# J7AEP_GPU_BXS464_WRAP0_GPU_SS_0_CORE_MMRS register map
Vendor: Texas Instruments
Registers are 64-bit, access per field, reset 0x0 unless marked. A register's access mark holds for its fields unless they carry their own. Offsets are as the file gives them; [hi:lo] are bit positions; lines under a group give offsets from that group; {n}, {i} and the like mark numbered series; 'fields as' and 'values as' point back to an identical list.

## J7AEP_GPU_BXS464_WRAP0_GPU_SS_0_CORE_MMRS (part 3 of 5)
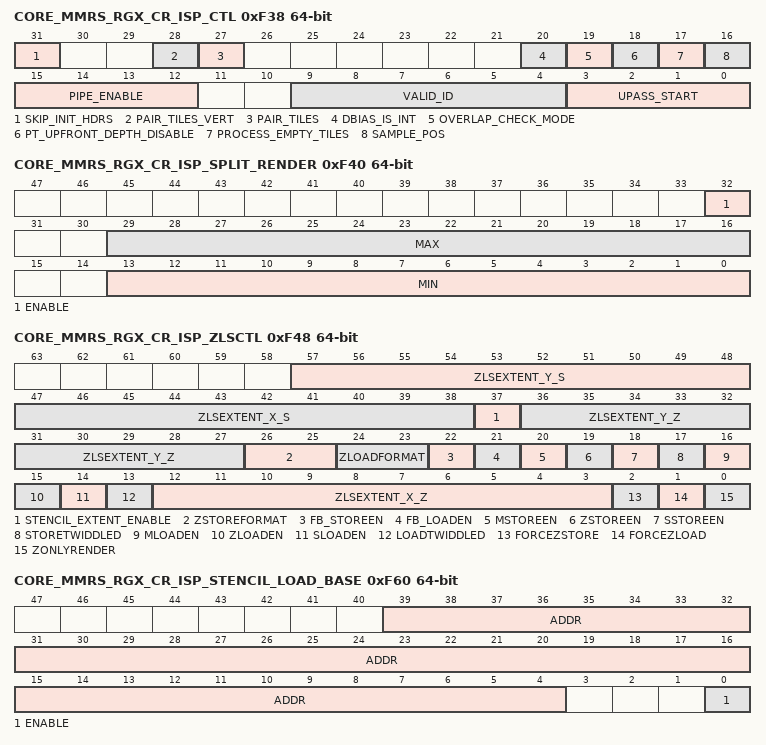
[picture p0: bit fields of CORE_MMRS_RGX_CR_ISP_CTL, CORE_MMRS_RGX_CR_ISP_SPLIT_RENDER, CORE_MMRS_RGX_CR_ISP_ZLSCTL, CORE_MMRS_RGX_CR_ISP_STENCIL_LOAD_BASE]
0xF38 CORE_MMRS_RGX_CR_ISP_CTL — ISP control register. This register contains the PIPE_NUM field which controls the number of tiles in flight within the IPP and IPF. The values to which this register should be set are dependent on not only the number of tiles in flight that are desired, but also the version of the architecture in use. For REL 1,2 Cores, this register can be programmed to values of 0x0-0x2 inclusive enabling 1, 2 and 3 tiles in flight for the single ISP in the system. In this system the IPP and IPF are both present in the same layout block. For REL 3,7 Cores, the IPP module is remote from the ISP module as the ISP belongs to the scalable elements in the design. A Cluster Group refers to the 4 USCs in a Phantom Block, which also contains an ISP. 1 Cluster Group = 1 IPP, and 1 ISP, 2 Cluster Groups = 1 IPP and 2 ISPs. The IPP module is configured using the register, and the tiles are split between them via the LSB of the Pipe Identifier. When 2 Cluster Groups (6 or 8 USC clusters) are present, as the value of PIPE_NUM is increased, the tile in flight are spread equally between ISP0 and ISP1, as below 0x0: - ISP0 (1 tile in flight) - ISP1 (Not Used - IDLE Pipe) 0x1: - ISP0 (1 tile in flight) - ISP1 (1 tile in flight) 0x2: - ISP0 (2 tiles in flight) - ISP1 (1 tile in flight) 0x3: - ISP0 (2 tiles in flight) - ISP1 (2 tiles in flight) 0x4: - ISP0 (3 tiles in flight) - ISP1 (2 tiles in flight) 0x5: - ISP0 (3 tiles in flight) - ISP1 (3 tiles in flight) 0x6: - ISP0 (4 tiles in flight) - ISP1 (3 tiles in flight) 0x7: - ISP0 (4 tiles in flight) - ISP1 (4 tiles in flight) Value of 0,2,4,6 should never be use on a 8 USC system, as they result in internal GPU imbalance. When 1 Cluster Group is present (1,2,4 USC clusters) , as the value of PIPE_NUM is increased, the tiles in flight will increase every power of 2, since ISP1 is not present. 0x0: - ISP0 (1 tile in flight) 0x2: - ISP0 (2 tiles in flight) 0x4: - ISP0 (3 tiles in flight) 0x6: - ISP0 (4 tiles in flight) A value which is higher than the number of IPF pipelines will result in the maximum number of pipelines being used. However, the number of pipelines being used should always be less than or equal to the number of tiles which the USC is able to concurrently process (i. e. the number of partitions). In a 4 or 8 cluster system there is 1 partition per tile. In a 2 cluster system there are 2 partitions per tile and in a 1 cluster system there are 4 partitions per tile. Effectively this means this register should be programmed according to the number of partitions available in the USC. NUM_TILES_PER_USC: 00 : 1 tile 01 : 2 tiles in the flight per usc cluster enabled 11 : 2 tiles in the flight per usc cluster enabled
  [31] SKIP_INIT_HDRS rw — Used to enable skipping of initial region headers based on gpu offset '0': reads all region headers and discards the ones not needed. '1': skip reading of region headers based on gpu offset
  [28] PAIR_TILES_VERT rw — If set, causes IPF to pair tiles vertically within its pipeline.
  [27] PAIR_TILES rw — If set, causes IPF to pair tiles within its pipeline.
  [20] DBIAS_IS_INT rw — When set, depth bias value is a signed integer
  [19] OVERLAP_CHECK_MODE rw — 0 - different samples for the same pixel will be sent to different pass groups for translucent objects [pixel to pixel overlap test] 1 - different samples for the same pixel will be sent as the same pass group [sample to sample overlap test]
  [18] PT_UPFRONT_DEPTH_DISABLE rw — When set, disable UPFRONT depth test in the Depthsorter
  [17] PROCESS_EMPTY_TILES rw — When set empty tiles are always processed rather than being suppressed
  [16] SAMPLE_POS rw — Specifies the sampling rule to be used when calculating the endpoint adjustment for thin lines
  [15:12] PIPE_ENABLE rw — Tiles-in-flight
  [9:4] VALID_ID rw — Triangle validation value
  [3:0] UPASS_START rw — User pass start value
0xF40 CORE_MMRS_RGX_CR_ISP_SPLIT_RENDER
  [32] ENABLE rw
  [29:16] MAX rw — Render up to and including this value
  [13:0] MIN rw — Render up from and including this value
0xF48 CORE_MMRS_RGX_CR_ISP_ZLSCTL — ISP Z Load/Store & format global control register
  [57:48] ZLSEXTENT_Y_S rw — For stencil buffer, the value calculation is the same as ZLSEXTENT_Y_Z
  [47:38] ZLSEXTENT_X_S rw — For stencil buffer, the value calculation is the same as ZLSEXTENT_X_Z
  [37] STENCIL_EXTENT_ENABLE rw — When this bit is '1', stencil buffer will use zlsextent_x/y_s value to calculate zload/store address, otherwise, zlsextent_x/y_z value will be used. The default value is '0' which disables this new function.
  [36:27] ZLSEXTENT_Y_Z rw — For Depth buffer Display width of Y in tiles minus one: 0x000 1 tile, 0x001 2 tiles, .. , 0x2FF 1024 tiles, zlsextent_y = total_samples_y / 32 samples in non-msaa, 4xmsaa mode = total_samples_y / 64 samples in 2xmsaa, 8xmsaa mode. In strided mode, zlsextent_y is set up to above result. In twiddled mode, zlsextent_y uses above result and rounds the value up to the nearest value which is power of 2.
  [26:25] ZSTOREFORMAT rw
  [24:23] ZLOADFORMAT rw
  [22] FB_STOREEN rw — when set, frame buffer compression store is enabled
  [21] FB_LOADEN rw — when set, frame buffer decompression load is enabled
  [20] MSTOREEN rw — When set and ZSTOREFORMAT = 0x0, mask plane is stored within msb of IEEE format, when set and ZSTOREFORMAT = 0x3, mask plane is stored at bit position 31 of IEEE format, when set for other format, if mask_store_base_enable = '1', background object mask data '0' is stored into separate memory address, when set for other format, if mask_store_base_enable = '0', mask data '0' is stored into separate meory address
  [19] ZSTOREEN rw — When set to 1, if the ZSTORE bit in the region header is also set then the depth buffer is stored to memory after each tile is processed
  [18] SSTOREEN rw — When set to 1, if the ZSTORE bit in the region header is also set then the stencil buffer is stored to memory after each tile is processed
  [17] STORETWIDDLED rw — When set to 1 depth and stencil data is written out in Twiddled order.
  [16] MLOADEN rw — When set and ZLOADFORMAT = 0x0, mask plane is loaded from msb of IEEE format, when set and ZLOADFORMAT = 0x3, mask plane is loaded from the bit position 31 of IEEE format, when set for other format, if mask_load_base_enable = '1', mask plane is loaded from separate memory address, when set for other format, if mask_load_base_enable = '0', background object mask data is used
  [15] ZLOADEN rw — When set to 1, if the ZLOAD bit in the region header is also set then the depth buffer is read from memory prior to tile processing
  [14] SLOADEN rw — When set to 1, if the ZLOAD bit in the region header is also set then the stencil buffer is read from memory prior to tile processing
  [13] LOADTWIDDLED rw — When set to 1 depth, stencil data is loaded in Twiddled order
  [12:3] ZLSEXTENT_X_Z rw — For depth buffer, Display width of X in tiles minus one: 0x000 1 tile, 0x001 2 tiles, .. , 0x2FF 1024 tiles. For different msaa mode, 1xmsaa = 1 x [32,32] pixels = 32x1 x 32x1 = 1024 samples = 32 x 32 samples, 2xmsaa = 2 x [32,32] pixels = 32x1 x 32x2 = 2048 samples = 32 x 64 samples, 4xmsaa = 4 x [32,16] pixels = 32x2 x 16x2 = 2048 samples = 64 x 32 samples, 8xmsaa = 8 x [16,16] pixels = 16x2 x 16x4 = 2048 samples = 32 x 64 samples, So zlsextent_x = total_samples_x / 32 samples when non-msaa, 2xmsaa, 8xmsaa zlsextent_x = total_samples_x / 64 samples when 4xmsaa In strided mode, zlsextent_x is set up to above result. In twiddled mode, zlsextent_x uses above result and rounds the value up to the neareast value which is power of 2.
  [2] FORCEZSTORE rw — If set to 1 the depth/stencil buffer is always stored at the end of each tile irrespective of the region header ZSTORE bit.
  [1] FORCEZLOAD rw — If set to 1 the depth/stencil buffer is always loaded at the start of each tile irrespective of the region header ZLOAD bit.
  [0] ZONLYRENDER rw — When set, only the Z buffer is rendered. Opaque and translucent objects are stencil and depth tested as usual but no pixel spans are emitted to the PDS Pixel presenter. Pixels within punch through and depth feedback objects are emitted on their first pass as a result of passing the up-front depth test by default. However, on their feedback depth test, these pixels will not be output regardless of the depth test result. The intention is to calculate a scene Z buffer without doing any further rendering.
0xF50 CORE_MMRS_RGX_CR_ISP_ZLOAD_BASE — Base address in memory of the Z Buffer base address to load into the ISP for non-compressed ZLS formats.
  [39:4] ADDR rw — 1TB Addressable, 16byte aligned Base Address of the Z Buffer Load base address
0xF58 CORE_MMRS_RGX_CR_ISP_ZSTORE_BASE — Base address in memory of the Z Buffer base address to store into the ISP for non-compressed ZLS formats.
  [39:4] ADDR rw — 1TB Addressable, 16byte aligned Base Address of the Z Buffer Store base address
0xF60 CORE_MMRS_RGX_CR_ISP_STENCIL_LOAD_BASE — Base address in memory of the Stencil Buffer base address to load into the ISP for non-compressed ZLS formats. This alternate stencil buffer base address is selectable based on the enable bit.
  [39:4] ADDR rw — 1TB Addressable, 16byte aligned Base Address of the Z Buffer Load base address
  [0] ENABLE rw — When set to 1, enables fetching of stencil from a separate base address
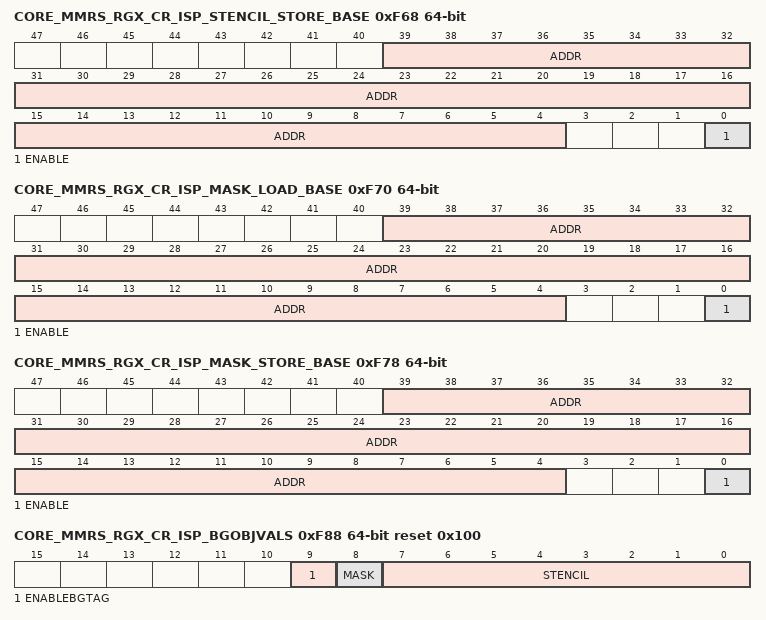
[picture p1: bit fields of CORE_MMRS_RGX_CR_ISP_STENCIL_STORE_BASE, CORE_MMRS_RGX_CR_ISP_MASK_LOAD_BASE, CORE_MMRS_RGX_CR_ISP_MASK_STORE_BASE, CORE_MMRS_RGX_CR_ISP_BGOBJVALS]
0xF68 CORE_MMRS_RGX_CR_ISP_STENCIL_STORE_BASE — Base address in memory of the Stencil Buffer base address to store into the ISP for non-compressed ZLS formats. This alternate stencil buffer base address is selectable based on the enable bit.
  fields as CORE_MMRS_RGX_CR_ISP_STENCIL_LOAD_BASE
0xF70 CORE_MMRS_RGX_CR_ISP_MASK_LOAD_BASE — Base address in memory of the Mask Buffer base address to load into the ISP for non-compressed ZLS formats. This alternate mask buffer base address is selectable based on the enable bit.
  [39:4] ADDR rw — 1TB Addressable, 16byte aligned Base Address of the Z Buffer Load base address
  [0] ENABLE rw — When set to 1, enables fetching of mask from a separate base address
0xF78 CORE_MMRS_RGX_CR_ISP_MASK_STORE_BASE — Base address in memory of the Mask Buffer base address to store into the ISP for non-compressed ZLS formats. This alternate mask buffer base address is selectable based on the enable bit.
  fields as CORE_MMRS_RGX_CR_ISP_MASK_LOAD_BASE
0xF80 CORE_MMRS_RGX_CR_ISP_BGOBJDEPTH — The ISP operates by comparing depth values of incoming objects with the results of previous depth compares, in order to make sure there are no unitialised values at the start of the tile or to cover pixels where there are no objects in the scene a default background object is configured under register control. This register provides the floating point depth value for the hardware background object.
  [31:0] VALUE rw — Note, the format in this register has to be consistent with the format defined by ZLS_STORE_FORMAT register. If depth buffer is F32, then the value here should be IEEE 754 single precisoin floating point If depth buffer is /INT16,then the value here should be UNORM24/UNORM16 foramt as well. Out of Range value will cause un-defined behavior.
0xF88 CORE_MMRS_RGX_CR_ISP_BGOBJVALS reset 0x100 — This register provides enable, mask and stencil information for the hardware background object.
  [9] ENABLEBGTAG rw — When set to 1, at the start of each tile the ISP tag buffer is initialised with the background object tag [default = 1]
  [8] MASK rw — Hardware background object mask plane
  [7:0] STENCIL rw — Hardware background object stencil
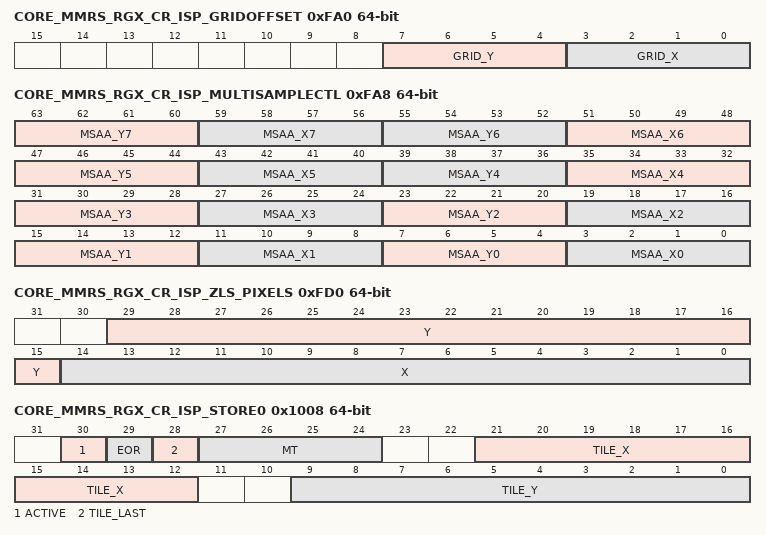
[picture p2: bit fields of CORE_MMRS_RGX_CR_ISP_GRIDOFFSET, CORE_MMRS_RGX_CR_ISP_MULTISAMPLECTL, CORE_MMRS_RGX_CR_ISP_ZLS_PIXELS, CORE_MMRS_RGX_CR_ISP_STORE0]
0xFA0 CORE_MMRS_RGX_CR_ISP_GRIDOFFSET — Sample position grid offset for use when MSAA/ODAA is DISABLED DX (0.0,0.0) OpenGL (0.5,0.5) Acts as the 9th multisample position when MSAA is ENABLED.
  [7:4] GRID_Y rw — Unsigned sub-pixel offset
  [3:0] GRID_X rw — Unsigned sub-pixel offset
0xFA8 CORE_MMRS_RGX_CR_ISP_MULTISAMPLECTL rw — Sample position grid offset for use in 2x, 4x, 8xMSAA and ODAA modes.
  [8n+7:8n+4] MSAA_Y{n} (n=3..7) — Unsigned sub-pixel offset for the {n+1}th multisample Y position
  [8n+3:8n] MSAA_X{n} (n=3..7) — Unsigned sub-pixel offset for the {n+1}th multisample X position
  [23:20] MSAA_Y2 — Unsigned sub-pixel offset for the 3rd multisample Y position
  [19:16] MSAA_X2 — Unsigned sub-pixel offset for the 3rd multisample X position
  [15:12] MSAA_Y1 — Unsigned sub-pixel offset for the 2nd multisample Y position
  [11:8] MSAA_X1 — Unsigned sub-pixel offset for the 2nd multisample X position
  [7:4] MSAA_Y0 — Unsigned sub-pixel offset for the 1st multisample Y position
  [3:0] MSAA_X0 — Unsigned sub-pixel offset for the 1st multisample X position
0xFB0 CORE_MMRS_RGX_CR_ISP_SCISSOR_BASE
  [39:2] ADDR rw — 1TB range, 32-bit aligned base address
0xFB8 CORE_MMRS_RGX_CR_ISP_DBIAS_BASE
  [39:2] ADDR rw — 1TB range, 32-bit aligned base address
0xFC0 CORE_MMRS_RGX_CR_ISP_OCLQRY_BASE — Base address for occlusion query counter values. For multiple phantom system, base address could be set differently and driver needs to sum up the result from different phantoms which have same occlusion query index.
  [39:4] ADDR rw — 1TB range, 128-bit aligned base address
0xFC8 CORE_MMRS_RGX_CR_ISP_PIXEL_BASE — Base address for control stream and primitive blocks.
  [39:34] ADDR rw — 1TB range, 16GB granularity
0xFD0 CORE_MMRS_RGX_CR_ISP_ZLS_PIXELS — screen size in pixel numbers for ZLS.
  [29:15] Y rw — Display width of Y in pixels minus one. 0x000 1 pixel, 0x001 2 pixels, ..., 0x7FFF 1024*32 pixels. Subtile only supports for non-msaa mode depth load/store, so For non-msaa mode, if framebuffer compression, or separate mask or separate stencil is enabled, [4 .. 0] has to be set to x1F. For 2xmsaa mode, [4 .. 0] has to be set to x1F. For 4xmsaa mode, [3 .. 0] has to be set to xF. For 8xmsaa mode, [3 .. 0] has to be set to xF.
  [14:0] X rw — Display width of X in pixels minus one. 0x000 1 pixel, 0x001 2 pixels, ..., 0x7FFF 1024*32 pixels. Subtile only supports for non-msaa mode depth load/store, so For non-msaa mode, if framebuffer compression, or separate mask or separate stencil is enabled, [4 .. 0] has to be set to x1F. For 2xmsaa mode, [4 .. 0] has to be set to x1F. For 4xmsaa mode, [4 .. 0] has to be set to x1F. For 8xmsaa mode, [3 .. 0] has to be set to xF.
0xFD8 CORE_MMRS_RGX_CR_ISP_CTL2 reset 0x10
  [4:0] DEPTHBUFFERS_IN_USE rw — Specifies the number of depth buffers to use
0x1000 CORE_MMRS_RGX_CR_ISP_START_CONTEXT_STORE — Writing '1' to this register initiates a 3D context store
  [0] PULSE wo
0x1008 CORE_MMRS_RGX_CR_ISP_STORE0 ro — ISP context store register
  [30] ACTIVE, [29] EOR, [28] TILE_LAST, [27:24] MT, [21:12] TILE_X, [9:0] TILE_Y
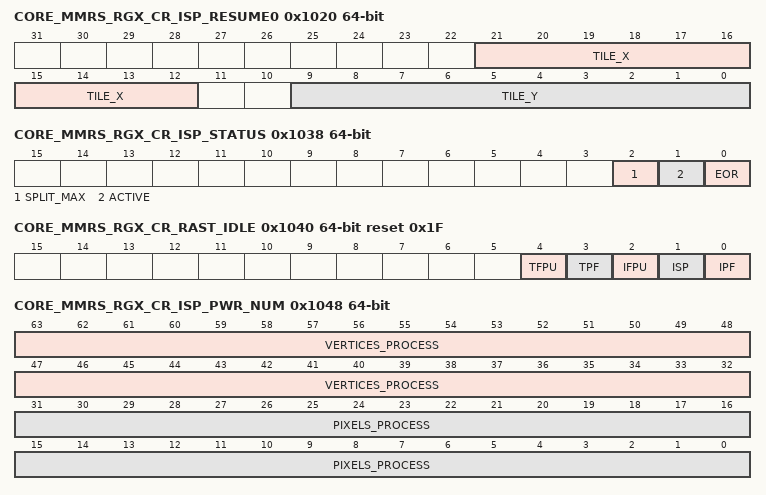
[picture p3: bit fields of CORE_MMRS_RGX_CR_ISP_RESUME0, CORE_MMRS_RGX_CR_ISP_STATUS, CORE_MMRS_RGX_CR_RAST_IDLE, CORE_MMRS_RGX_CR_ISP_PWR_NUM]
0x1020 CORE_MMRS_RGX_CR_ISP_RESUME0 — ISP context resume register
  [21:12] TILE_X rw, [9:0] TILE_Y rw
0x1038 CORE_MMRS_RGX_CR_ISP_STATUS ro — ISP status registers
  [2] SPLIT_MAX — Split Render Maximum Threshold has been Exceeded
  [1] ACTIVE — ISP is Active, first tile in the render has been assigned
  [0] EOR — ISP has assigned the last tile in the render
0x1040 CORE_MMRS_RGX_CR_RAST_IDLE ro reset 0x1F
  [4] TFPU — TFPU Module IDLE
  [3] TPF — TPF Module IDLE
  [2] IFPU — IFPU Module IDLE
  [1] ISP — ISP Module IDLE
  [0] IPF — IPF Module IDLE
0x1048 CORE_MMRS_RGX_CR_ISP_PWR_NUM ro
  [63:32] VERTICES_PROCESS — Number of vertices processed
  [31:0] PIXELS_PROCESS — Number of depth tested pixels[non-MSAA] or samples[MSAA] processed
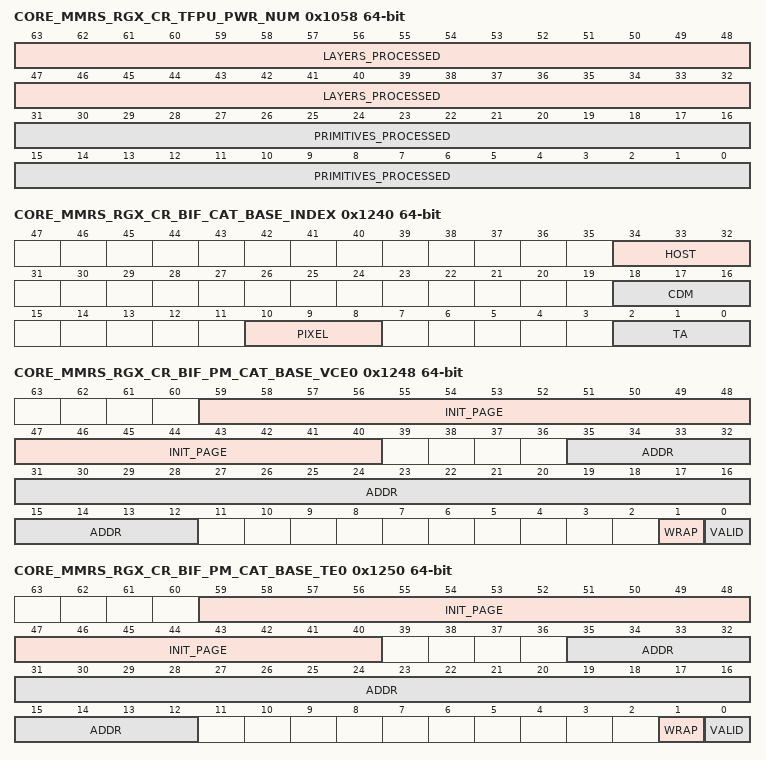
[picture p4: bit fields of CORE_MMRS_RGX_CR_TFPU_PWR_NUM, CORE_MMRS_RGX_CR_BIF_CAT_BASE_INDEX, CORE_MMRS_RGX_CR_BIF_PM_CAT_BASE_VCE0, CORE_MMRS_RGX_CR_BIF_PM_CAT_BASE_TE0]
0x1058 CORE_MMRS_RGX_CR_TFPU_PWR_NUM ro
  [63:32] LAYERS_PROCESSED — Number of layers processed
  [31:0] PRIMITIVES_PROCESSED — Number of primitives processed
0x11D0 CORE_MMRS_RGX_CR_ISP_MERGE_LOWER_X reset 0x378930A3 — Used by the IFPU to generate the angle vectors used for triangle merging
  [31:0] VALUE rw — tan[15]/16k screen size
0x11D8 CORE_MMRS_RGX_CR_ISP_MERGE_LOWER_Y reset 0x378930A3 — Used by the IFPU to generate the angle vectors used for triangle merging
  [31:0] VALUE rw — tan[15]/16k screen size
0x11E0 CORE_MMRS_RGX_CR_ISP_MERGE_UPPER_X reset 0x38DDB3D7
  [31:0] VALUE rw — tan[60]/16k screen size
0x11E8 CORE_MMRS_RGX_CR_ISP_MERGE_UPPER_Y reset 0x38DDB3D7 — Used by the IFPU to generate the angle vectors used for triangle merging
  [31:0] VALUE rw — tan[60]/16k screen size
0x11F0 CORE_MMRS_RGX_CR_ISP_MERGE_SCALE_X reset 0x48800000
  [31:0] VALUE rw — 16 * default screen size of 16k
0x11F8 CORE_MMRS_RGX_CR_ISP_MERGE_SCALE_Y reset 0x48800000 — Used by the IFPU to generate the angle vectors used for triangle merging
  [31:0] VALUE rw — 16 * default screen size of 16k
{0x1200+8i} CORE_MMRS_RGX_CR_BIF_CAT_BASE{i} (i=0..7)
  [39:12] ADDR rw
0x1240 CORE_MMRS_RGX_CR_BIF_CAT_BASE_INDEX — Index registers per data master. Byte aligned fields to allow byte-masked access
  [34:32] HOST rw — Catalogue Base number for HOST data master
  [18:16] CDM rw — Catalogue Base number for CDM data master
  [10:8] PIXEL rw — Catalogue Base number for PIXEL data master
  [2:0] TA rw — Catalogue Base number for TA data master
0x1248 CORE_MMRS_RGX_CR_BIF_PM_CAT_BASE_VCE0 — PM catalogue base address for VCE context 0
  [59:40] INIT_PAGE rw
  [35:12] ADDR rw
  [1] WRAP rw — Indicates address space has been fully allocated
  [0] VALID rw
0x1250 CORE_MMRS_RGX_CR_BIF_PM_CAT_BASE_TE0 — PM catalogue base address for TE context 0
  [59:40] INIT_PAGE rw, [35:12] ADDR rw, [1] WRAP rw, [0] VALID rw
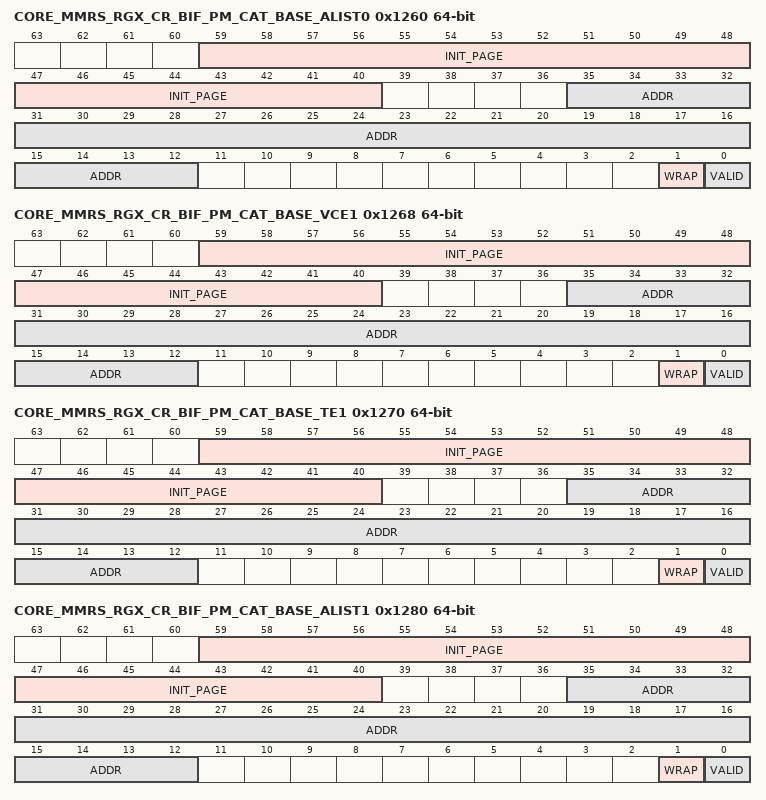
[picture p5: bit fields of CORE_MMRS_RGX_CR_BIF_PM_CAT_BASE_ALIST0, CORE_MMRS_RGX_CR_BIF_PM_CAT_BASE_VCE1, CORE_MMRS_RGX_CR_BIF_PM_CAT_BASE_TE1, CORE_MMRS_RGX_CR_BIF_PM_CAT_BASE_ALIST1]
0x1260 CORE_MMRS_RGX_CR_BIF_PM_CAT_BASE_ALIST0 — PM catalogue base address for ALIST context 0
  [59:40] INIT_PAGE rw, [35:12] ADDR rw, [1] WRAP rw, [0] VALID rw
0x1268 CORE_MMRS_RGX_CR_BIF_PM_CAT_BASE_VCE1 — PM catalogue base address for VCE context 1
  [59:40] INIT_PAGE rw, [35:12] ADDR rw, [1] WRAP rw, [0] VALID rw
0x1270 CORE_MMRS_RGX_CR_BIF_PM_CAT_BASE_TE1 — PM catalogue base address for TE context 1
  [59:40] INIT_PAGE rw, [35:12] ADDR rw, [1] WRAP rw, [0] VALID rw
0x1280 CORE_MMRS_RGX_CR_BIF_PM_CAT_BASE_ALIST1 — PM catalogue base address for ALIST context 1
  [59:40] INIT_PAGE rw, [35:12] ADDR rw, [1] WRAP rw, [0] VALID rw
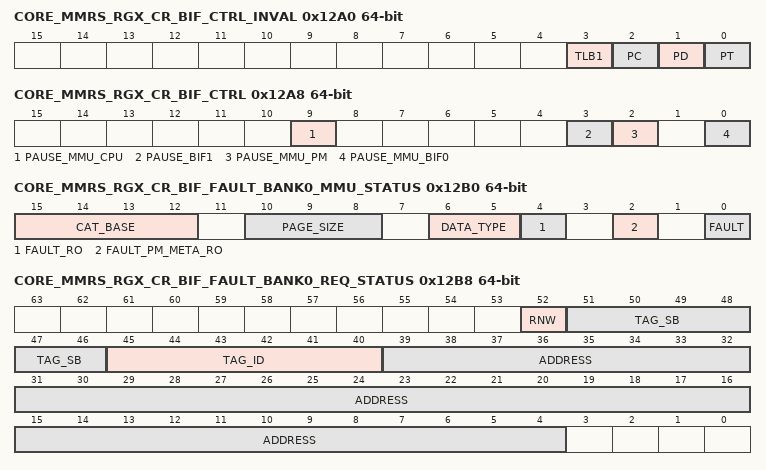
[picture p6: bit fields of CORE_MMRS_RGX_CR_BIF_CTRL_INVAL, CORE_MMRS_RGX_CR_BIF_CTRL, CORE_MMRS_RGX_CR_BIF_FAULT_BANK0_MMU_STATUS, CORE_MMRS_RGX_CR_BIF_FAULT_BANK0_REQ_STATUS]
0x12A0 CORE_MMRS_RGX_CR_BIF_CTRL_INVAL — Invalidation bits allowing BIF/MMU to clear when invalidation complete
  [3] TLB1 wo, [2] PC wo, [1] PD wo, [0] PT wo
0x12A8 CORE_MMRS_RGX_CR_BIF_CTRL — Miscellaneous controls
  [9] PAUSE_MMU_CPU rw — Stalls input to CPU MMU
  [3] PAUSE_BIF1 rw — Stalls BIF1 pipeline
  [2] PAUSE_MMU_PM rw — Stalls PM input to MMU
  [0] PAUSE_MMU_BIF0 rw — Stalls BIF0 input to MMU
0x12B0 CORE_MMRS_RGX_CR_BIF_FAULT_BANK0_MMU_STATUS ro — Indicates a fault has occurred on bank 0 and provides details of fault
  [15:12] CAT_BASE — Catalogue base address number
  [10:8] PAGE_SIZE
  [6:5] DATA_TYPE — MMU data type that was invalid [on valid fault]
  [4] FAULT_RO — Indicates read-only fault['1'] or valid fault['0']
  [2] FAULT_PM_META_RO — Indicates pm/meta protected region fault
  [0] FAULT — Indicates a fault has occured
0x12B8 CORE_MMRS_RGX_CR_BIF_FAULT_BANK0_REQ_STATUS ro — Provides details of the request that faulted on bank 0
  [52] RNW, [51:46] TAG_SB, [45:40] TAG_ID, [39:4] ADDRESS
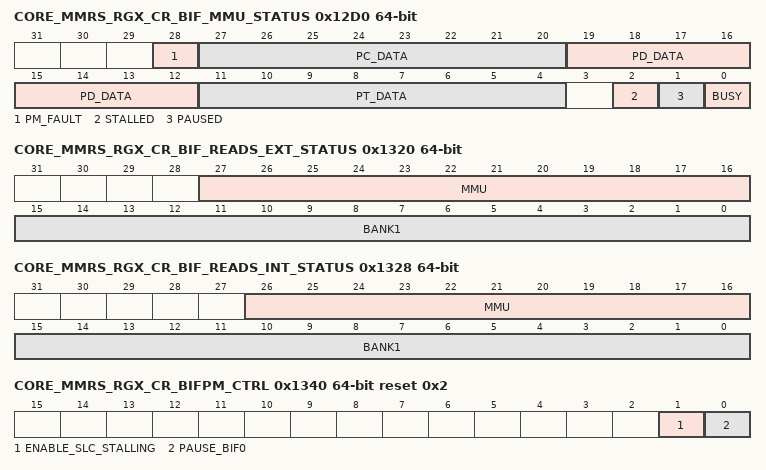
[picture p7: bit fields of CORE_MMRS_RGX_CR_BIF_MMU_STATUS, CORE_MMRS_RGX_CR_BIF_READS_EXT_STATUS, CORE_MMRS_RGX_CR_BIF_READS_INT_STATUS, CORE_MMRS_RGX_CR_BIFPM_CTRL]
0x12D0 CORE_MMRS_RGX_CR_BIF_MMU_STATUS ro — General MMU status
  [28] PM_FAULT, [27:20] PC_DATA, [19:12] PD_DATA, [11:4] PT_DATA, [2] STALLED, [1] PAUSED, [0] BUSY
0x1320 CORE_MMRS_RGX_CR_BIF_READS_EXT_STATUS ro — Outstanding read data external to BIF for BIF128 and MMU
  [27:16] MMU, [15:0] BANK1
0x1328 CORE_MMRS_RGX_CR_BIF_READS_INT_STATUS ro — Outstanding 256-bit read data in return data FIFO for BIF128 and MMU
  [26:16] MMU, [15:0] BANK1
0x1330 CORE_MMRS_RGX_CR_BIFPM_READS_INT_STATUS ro — Outstanding 256-bit read data in return data FIFO for BIF256
  [15:0] BANK0
0x1338 CORE_MMRS_RGX_CR_BIFPM_READS_EXT_STATUS ro — Outstanding 256-bit read data external to BIF for BIF256
  [15:0] BANK0
0x1340 CORE_MMRS_RGX_CR_BIFPM_CTRL reset 0x2 — Miscellaneous controls
  [1] ENABLE_SLC_STALLING rw — Enables BIF to stall returns from SLC so that requests can be made even when there is no space in the BIF return buffer [only when no chance of lockup]
  [0] PAUSE_BIF0 rw — Stalls BIF0 pipeline
0x1348 CORE_MMRS_RGX_CR_BIFPM_CTRL_INVAL — Invalidation bits allowing BIF to clear when invalidation complete
  [0] TLB0 wo
0x1350 CORE_MMRS_RGX_CR_BIFPM_STATUS_MMU ro — Outstanding MMU requests from BIF0
  [7:0] REQUESTS
0x1358 CORE_MMRS_RGX_CR_BIF_STATUS_MMU ro — Outstanding MMU requests from BIF1
  [7:0] REQUESTS
0x1370 CORE_MMRS_RGX_CR_BIF_BLACKPEARL_PWR ro — Power monitoring register
  [31:0] NUM_256BIT_TRANS — Number of 256-bit transactions
0x1378 CORE_MMRS_RGX_CR_BIF_JONES_PWR ro — Power monitoring register
  [31:0] NUM_256BIT_TRANS — Number of 256-bit transactions
0x13E0 CORE_MMRS_RGX_CR_BIF_FAULT_READ — Specifies physical address to read from in the event of a faulting read request from BIF1
  [39:4] ADDRESS rw
0x13E8 CORE_MMRS_RGX_CR_BIF_PWR ro — Power monitoring register
  [31:0] NUM_256BIT_TRANS — Number of 256-bit transactions
0x13F8 CORE_MMRS_RGX_CR_BIF_MCU_RESERVED — Allows driver to change the amount of space in the return data FIFO reserved for the MCU
  [4:0] SPACE wo — Granularity of 8 spaces, minimum legal value 0x1
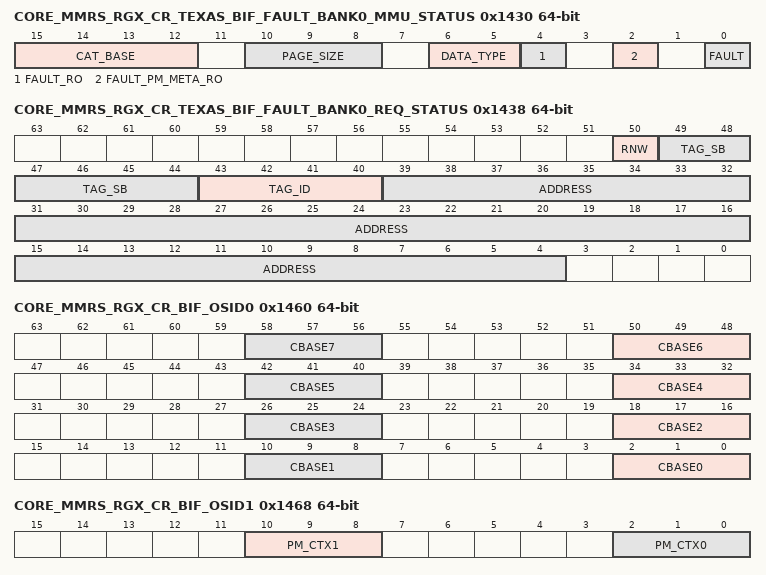
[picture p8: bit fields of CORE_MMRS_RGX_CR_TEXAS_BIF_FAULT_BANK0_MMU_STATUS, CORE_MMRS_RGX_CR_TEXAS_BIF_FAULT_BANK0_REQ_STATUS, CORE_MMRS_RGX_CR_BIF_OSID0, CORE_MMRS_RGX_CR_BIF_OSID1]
0x1430 CORE_MMRS_RGX_CR_TEXAS_BIF_FAULT_BANK0_MMU_STATUS ro — Indicates a fault has occurred on bank 0 and provides details of fault
  fields as CORE_MMRS_RGX_CR_BIF_FAULT_BANK0_MMU_STATUS
0x1438 CORE_MMRS_RGX_CR_TEXAS_BIF_FAULT_BANK0_REQ_STATUS ro — Provides details of the request that faulted on bank 0
  [50] RNW, [49:44] TAG_SB, [43:40] TAG_ID, [39:4] ADDRESS
0x1440 CORE_MMRS_RGX_CR_TEXAS_BIFPM_READS_INT_STATUS ro — Outstanding 256-bit read data in return data FIFO for BIF256
  [15:0] BANK0
0x1448 CORE_MMRS_RGX_CR_TEXAS_BIFPM_READS_EXT_STATUS ro — Outstanding 256-bit read data external to BIF for BIF256
  [15:0] BANK0
0x1450 CORE_MMRS_RGX_CR_TEXAS_BIFPM_STATUS_MMU ro — Outstanding MMU requests from BIF0
  [7:0] REQUESTS
0x1460 CORE_MMRS_RGX_CR_BIF_OSID0 — Defines OSID for each CAT_BASE
  [8n+2:8n] CBASE{n} rw (n=0..7) — OSID for CAT BASE {n}
0x1468 CORE_MMRS_RGX_CR_BIF_OSID1 — Defines OSID for each data master
  [10:8] PM_CTX1 rw — OSID for VCE1, TE1 and ALIST1
  [2:0] PM_CTX0 rw — OSID for VCE0, TE0 and ALIST0
0x1470 CORE_MMRS_RGX_CR_TFBC_ZLS_COMPRESSOR_CFI — ZLS TFBC compressor cache control flush
  [0] PENDING rw — Write a one to this register to initiate a flush of the ZLS TFBC Compressor cache. This register can be read. If the value is one, the this indicates a flush operation is underway.
0x1478 CORE_MMRS_RGX_CR_TFBC_PBE_COMPRESSOR_CFI — PBE TFBC compressor cache control flush
  [0] PENDING rw — Write a one to this register to initiate a flush of the PBE TFBC Compressor cache. This register can be read. If the value is one, the this indicates a flush operation is underway.
0x1480 CORE_MMRS_RGX_CR_TFBC_ZLS_DECOMPRESSOR_CFI — ZLS TFBC decompressor cache invalidation
  [0] INVALIDATE wo — Informs the ZLS decompressor to invalidate its cache.
0x1488 CORE_MMRS_RGX_CR_TFBC_TPU_DECOMPRESSOR_CFI — TPU TFBC decompressor cache invalidation
  [0] INVALIDATE wo — Informs the TPU decompressor to invalidate its cache.
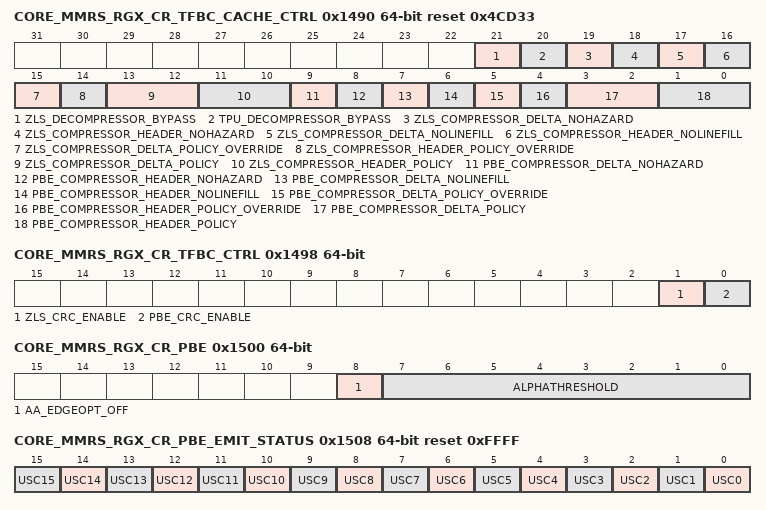
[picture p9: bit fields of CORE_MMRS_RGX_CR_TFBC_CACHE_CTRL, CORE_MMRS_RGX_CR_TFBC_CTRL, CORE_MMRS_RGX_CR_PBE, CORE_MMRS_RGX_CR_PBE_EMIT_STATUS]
0x1490 CORE_MMRS_RGX_CR_TFBC_CACHE_CTRL reset 0x4CD33 — TFBC compressor and decompressor cache control register
  [21] ZLS_DECOMPRESSOR_BYPASS rw — When set to 1, the ZLS decompressor cache is disabled.
  [20] TPU_DECOMPRESSOR_BYPASS rw — When set to 1, the TPU decompressor cache is disabled.
  [19] ZLS_COMPRESSOR_DELTA_NOHAZARD rw — When set to 1, the ZLS compressor no_hazard signal is set high to the SLC for delta writes. This will cause the TFBC to disable hazard checking in the SLC for delta writes.
  [18] ZLS_COMPRESSOR_HEADER_NOHAZARD rw — When set to 1, the ZLS compressor no_hazard signal is set high to the SLC for header writes. This will cause the TFBC to disable hazard checking in the SLC for header writes.
  [17] ZLS_COMPRESSOR_DELTA_NOLINEFILL rw — When set to 0, the ZLS compressor line fills data from memory before writing data back for deltas. When set to 1, the ZLS compressor does not line fill from memory for deltas.
  [16] ZLS_COMPRESSOR_HEADER_NOLINEFILL rw — When set to 0, the ZLS compressor line fills data from memory before writing data back for headers. When set to 1, the ZLS compressor does not line fill from memory for headers.
  [15] ZLS_COMPRESSOR_DELTA_POLICY_OVERRIDE rw — When set to 0, the ZLS compressor will use the SLC policy supplied by the ZLS for delta writes. When set to 1, the ZLS compressor will use the ZLS_COMPRESSOR_DELTA_POLICY for delta writes.
  [14] ZLS_COMPRESSOR_HEADER_POLICY_OVERRIDE rw — When set to 0, the ZLS compressor will use the SLC policy supplied by the ZLS for header writes. When set to 1, the ZLS compressor will use the ZLS_COMPRESSOR_HEADER_POLICY for header writes.
  [13:12] ZLS_COMPRESSOR_DELTA_POLICY rw — SLC cache policy applied to ZLS compressor delta writes when ZLS_COMPRESSOR_DELTA_POLICY_OVERRIDE is set to 1
  [11:10] ZLS_COMPRESSOR_HEADER_POLICY rw — SLC cache policy applied to ZLS compressor header writes when ZLS_COMPRESSOR_HEADER_POLICY_OVERRIDE is set to 1
  [9] PBE_COMPRESSOR_DELTA_NOHAZARD rw — When set to 1, the PBE compressor no_hazard signal is set high to the SLC for delta writes. This will cause the TFBC to disable hazard checking in the SLC for delta writes.
  [8] PBE_COMPRESSOR_HEADER_NOHAZARD rw — When set to 1, the PBE compressor no_hazard signal is set high to the SLC for header writes. This will cause the TFBC to disable hazard checking in the SLC for header writes.
  [7] PBE_COMPRESSOR_DELTA_NOLINEFILL rw — When set to 0, the PBE compressor line fills data from memory before writing data back for deltas. When set to 1, the PBE compressor does not line fill from memory for deltas.
  [6] PBE_COMPRESSOR_HEADER_NOLINEFILL rw — When set to 0, the PBE compressor line fills data from memory before writing data back for headers. When set to 1, the PBE compressor does not line fill from memory for headers.
  [5] PBE_COMPRESSOR_DELTA_POLICY_OVERRIDE rw — When set to 0, the PBE compressor will use the SLC policy supplied by the PBE for delta writes. When set to 1, the PBE compressor will use the PBE_COMPRESSOR_DELTA_POLICY for delta writes.
  [4] PBE_COMPRESSOR_HEADER_POLICY_OVERRIDE rw — When set to 0, the PBE compressor will use the SLC policy supplied by the PBE for header writes. When set to 1, the PBE compressor will use the PBE_COMPRESSOR_HEADER_POLICY for header writes.
  [3:2] PBE_COMPRESSOR_DELTA_POLICY rw — SLC cache policy applied to PBE compressor delta writes when PBE_COMPRESSOR_DELTA_POLICY_OVERRIDE is set to 1
  [1:0] PBE_COMPRESSOR_HEADER_POLICY rw — SLC cache policy applied to PBE compressor header writes when PBE_COMPRESSOR_HEADER_POLICY_OVERRIDE is set to 1
0x1498 CORE_MMRS_RGX_CR_TFBC_CTRL — General TFBC control register
  [1] ZLS_CRC_ENABLE rw — Enable the generation of CRCs for compression depth buffer writes.
  [0] PBE_CRC_ENABLE rw — Enable the generation of CRCs for compressed frame buffer writes.
0x1500 CORE_MMRS_RGX_CR_PBE — The PBE(Pixel back end) module scales and packs the pixel data before writing to memory, this register contains global control signals.
  [8] AA_EDGEOPT_OFF rw — Switches off the PBE-USE read optimisation during Anti aliasing mode. [This is typically for debug purposes only]
  [7:0] ALPHATHRESHOLD rw — Alpha threshold used when encoding 1555 format. If the internal 8bit Alpha value exceeds this value, then a 1 is written to the top bit of the output, otherwise a 0 is written
0x1508 CORE_MMRS_RGX_CR_PBE_EMIT_STATUS ro reset 0xFFFF — This register indicates if the PixelBE would stall the USE if there were another emit. '0' indicates that the PixelBE would stall the USC. '1' indicates that the PixelBE would not stall the USE.
  [n] USC{n} (n=0..15) — Pipe {n} status
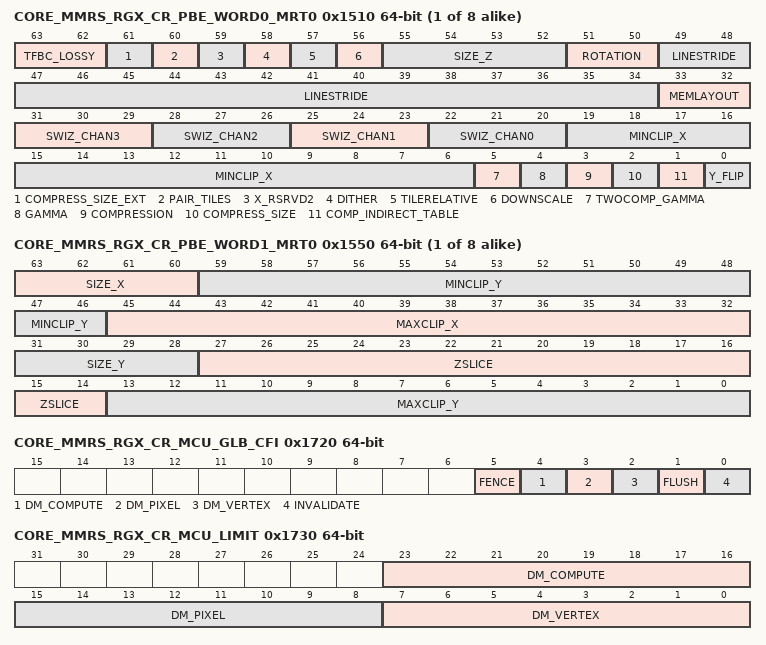
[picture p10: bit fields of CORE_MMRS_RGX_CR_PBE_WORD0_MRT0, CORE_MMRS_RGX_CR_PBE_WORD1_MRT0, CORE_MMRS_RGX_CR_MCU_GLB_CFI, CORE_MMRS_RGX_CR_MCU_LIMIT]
{0x1510+8i} CORE_MMRS_RGX_CR_PBE_WORD0_MRT{i} rw (i=0..7) — Pixel Back end State Word 0.
  [63:62] TFBC_LOSSY — Sets the lossy bit for frame buffer compression
  [61] COMPRESS_SIZE_EXT — Extra bit to support 32x2 compression size, used with COMPRESS_SIZE register bit to define 8x8; 16x4 or 32x2 size COMPRESS_SIZE_EXT COMPRESS_SIZE SIZE 0 0 8x8 0 1 16x4 1 0 32x2 1 1 reserved
  [60] PAIR_TILES — If set, then PBE will pair 16x16 tiles
  [59] X_RSRVD2 — Not used
  [58] DITHER — Enable dither
  [57] TILERELATIVE — Add tile offset
  [56] DOWNSCALE — Perform box filter downscale
  [55:52] SIZE_Z — Z Size in pixels [log 2]
  [51:50] ROTATION — Rotation angle
  [49:34] LINESTRIDE — Linestride in 2 pixel units. 0 == 2. Supports 32KDWORD stride memory write
  [33:32] MEMLAYOUT — Memory layout
  [3n+22:3n+20] SWIZ_CHAN{n} (n=0..3) — Swizzle for destination channel {n}
  [19:6] MINCLIP_X — Min X Clip
  [5] TWOCOMP_GAMMA — Sets the gamma mode for 2 component targets
  [4] GAMMA — Gamma enabled
  [3] COMPRESSION — Frame buffer Compression enabled
  [2] COMPRESS_SIZE — Block size for the compressor, used with COMPRESS_SIZE_EXT register bit to define 8x8; 16x4 or 32x2 size COMPRESS_SIZE_EXT COMPRESS_SIZE SIZE 0 0 8x8 0 1 16x4 1 0 32x2 1 1 reserved
  [1] COMP_INDIRECT_TABLE — If set indicates to the compressor that an indirect addressing is used otherwise direct addressing
  [0] Y_FLIP
{0x1550+8i} CORE_MMRS_RGX_CR_PBE_WORD1_MRT{i} rw (i=0..7) — Pixel Back end State Word 1.
  [63:60] SIZE_X — X Size in pixels [log 2]
  [59:46] MINCLIP_Y — Min Y Clip
  [45:32] MAXCLIP_X — Max X clip
  [31:28] SIZE_Y — Y Size in pixels [log 2]
  [27:14] ZSLICE — Slice number for render to 3D twiddle target
  [13:0] MAXCLIP_Y — Max Y clip
0x1590 CORE_MMRS_RGX_CR_PBE_PWR ro — Power monitoring register
  [31:0] NUM_PIXELS_PROCESSED — Number of on-edge/off-edge pixels per tile.
0x1720 CORE_MMRS_RGX_CR_MCU_GLB_CFI — Global flush and invalidation control for all Texture and Data Cache. Will flush then invalidate cache if both bit 0 & bit 1 set.
  [5] FENCE wo — When set, additionally perform a fence to external memory before signalling that a flush is complete
  [4] DM_COMPUTE wo — When set, perform operation on compute data master
  [3] DM_PIXEL wo — When set, perform operation on pixel data master
  [2] DM_VERTEX wo — When set, perform operation on vertex data master
  [1] FLUSH wo — When set, will flush cache based on data master
  [0] INVALIDATE wo — When set, will invalidate cache based on data master. This bit will also invalidate the L0 cache in the MADD and teh YUV cache in the TAG to reset the CSC coefficients.
0x1728 CORE_MMRS_RGX_CR_MCU_GLB_CFI_EVENT ro — Global flush and invalidation event for all Texture and Data Cache.
  [0] PENDING — 1 Indicate there is a pending global CFI operation on the MCU
0x1730 CORE_MMRS_RGX_CR_MCU_LIMIT — Define the maximum number of cache lines allowed to be allocated to each Data Master within the SLC. Note that values are specified per group with a value of 0x0 denoting no limit. Also note that the specified values operate as soft limits rather than hard limits and at any given time a Data Master may temporarily exceed its given cacheline limit by a small amount.
  [23:16] DM_COMPUTE rw — Maximum number of cachelines which can be used by the Compute data master
  [15:8] DM_PIXEL rw — Maximum number of cachelines which can be used by the Pixel data master
  [7:0] DM_VERTEX rw — Maximum number of cachelines which can be used by the Vertex data master
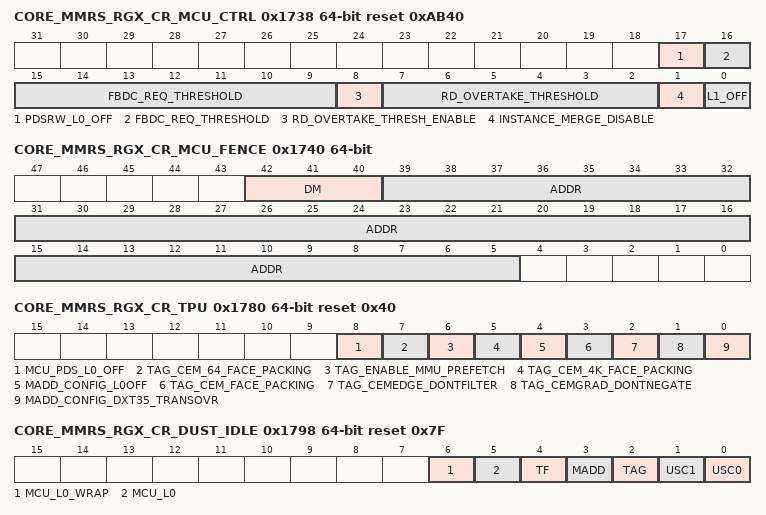
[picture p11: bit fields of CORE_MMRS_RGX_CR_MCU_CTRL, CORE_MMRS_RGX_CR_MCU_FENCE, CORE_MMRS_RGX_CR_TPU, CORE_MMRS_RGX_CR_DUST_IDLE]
0x1738 CORE_MMRS_RGX_CR_MCU_CTRL reset 0xAB40 — MCU control registers
  [17] PDSRW_L0_OFF rw — Turn off MCU PDSRW L0 cache
  [16:9] FBDC_REQ_THRESHOLD rw — Maximum number of outstanding requests each MCU group can have to the Framebuffer Decompression module
  [8] RD_OVERTAKE_THRESH_ENABLE rw — Enables the use of the threshold to limit the amount of overtaking which is permitted
  [7:2] RD_OVERTAKE_THRESHOLD rw — The number of read accesses which are permitted to overtake waiting Writebacks when enabled
  [1] INSTANCE_MERGE_DISABLE rw — Turn off instance merging in the MCU L1
  [0] L1_OFF rw — Turn off MCU L1
0x1740 CORE_MMRS_RGX_CR_MCU_FENCE — Defines the Data Master and Addresses used when the MCU optionally issues a Fence as part of a Flush operation. See MCU_GLB_CFI register for details.
  [42:40] DM rw — Data Master value to use when issuing a Fence
  [39:5] ADDR rw — Address value to use when issuing a Fence
0x1780 CORE_MMRS_RGX_CR_TPU reset 0x40 — Global control to TPU_MCU_L0|tpu
  [8] MCU_PDS_L0_OFF rw — Turn off MCU PDSL0 cache
  [7] TAG_CEM_64_FACE_PACKING rw — Pixel data master. Enable 64-byte alignment between CEM faces when set to 1. It applies for both when mipmap is enabled or disabled
  [6] TAG_ENABLE_MMU_PREFETCH rw — Enables generation of prefetch requests to the MMU
  [5] TAG_CEM_4K_FACE_PACKING rw — Pixel data master. Enable 4K-byte alignment between CEM faces when set to 1. It applies for both when mipmap is enabled or disabled
  [4] MADD_CONFIG_L0OFF rw — When set this disables MADD P0 L0 cache
  [3] TAG_CEM_FACE_PACKING rw — Pixel data master. Enable dword alignment between CEM faces when set to 1
  [2] TAG_CEMEDGE_DONTFILTER rw — Pixel data master. Disable filtering over edges/corners for CEM. When set to 1, HW will be seemfull, ie, always stay in the current map, always honour the addressmode. When set to 0, HW will be seemless, ie, ignore addressmode, filter between faces at the edges/corners
  [1] TAG_CEMGRAD_DONTNEGATE rw — Pixel data master. Disable negation for user supplied gradients for cem swap i. e. will only swap dudx etc not negate
  [0] MADD_CONFIG_DXT35_TRANSOVR rw — When set this disables alternative mode implied by colour0 > colour1 for DXT3 to DXT5
0x1788 CORE_MMRS_RGX_CR_TPU_YUV_CSC_COEFFICIENTS — Base address for the YUV CSC set of coefficients stored in memory for pixel data master
  [37:0] YUV_CSC_COEFFICIENTS_ADDRESS rw — Base address DWORD aligned for the location in memory of the CSC coefficients
0x1790 CORE_MMRS_RGX_CR_TPU_BORDER_COLOUR_TABLE_PDM — Base address for the border colour table
  [37:0] BORDER_COLOUR_TABLE_ADDRESS rw — Base address DWORD aligned for the location in memory of the border colour table for the PDM
0x1798 CORE_MMRS_RGX_CR_DUST_IDLE ro reset 0x7F
  [6] MCU_L0_WRAP — MCU L0 WRAP Module IDLE
  [5] MCU_L0 — MCU L0 Module IDLE
  [4] TF — TF Module IDLE
  [3] MADD — MADD Module IDLE
  [2] TAG — TAG Module IDLE
  [1] USC1 — USC1 Module IDLE
  [0] USC0 — USC0 Module IDLE
0x17A0 CORE_MMRS_RGX_CR_TPU_BORDER_COLOUR_TABLE_VDM — Base address for the border colour table
  [37:0] BORDER_COLOUR_TABLE_ADDRESS rw — Base address DWORD aligned for the location in memory of the border colour table for the VDM
0x17A8 CORE_MMRS_RGX_CR_TPU_BORDER_COLOUR_TABLE_CDM — Base address for the border colour table
  [37:0] BORDER_COLOUR_TABLE_ADDRESS rw — Base address DWORD aligned for the location in memory of the border colour table for the CDM
0x17B0 CORE_MMRS_RGX_CR_TPU_PWR_NUMBER_OF_TEXELS ro — Peformance counter associated with Power Monitoring.
  [31:0] VALUE — Number of texels requested per clock
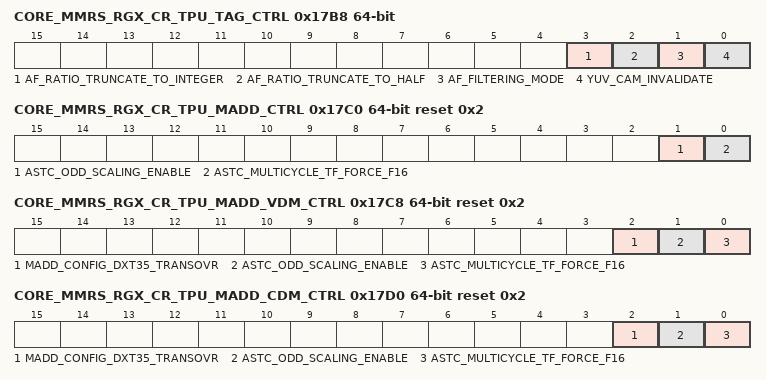
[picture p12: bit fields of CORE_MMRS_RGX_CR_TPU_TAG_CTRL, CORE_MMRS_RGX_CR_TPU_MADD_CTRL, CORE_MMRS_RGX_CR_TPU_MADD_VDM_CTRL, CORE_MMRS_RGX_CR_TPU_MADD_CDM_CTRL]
0x17B8 CORE_MMRS_RGX_CR_TPU_TAG_CTRL — Global control to TAG for the pixel data master
  [3] AF_RATIO_TRUNCATE_TO_INTEGER rw — 0 current mode, 1 clear the fractional part of the calculated AF ratio
  [2] AF_RATIO_TRUNCATE_TO_HALF rw — 0 current mode, 1 truncate the fractional part of the calculated AF ratio to 0. 5
  [1] AF_FILTERING_MODE rw — 0 current mode, 1 new mode.
  [0] YUV_CAM_INVALIDATE rw — When set, will invalidate YUV CSC CAM to reset the CSC coefficients. It should be set when the TPU is not performing CSC.
0x17C0 CORE_MMRS_RGX_CR_TPU_MADD_CTRL reset 0x2 — Global control to MADD for pixel data master
  [1] ASTC_ODD_SCALING_ENABLE rw — When set, ASTC encoded texels use the odd U16->F16 scaling in the TF. When zero, the usual scaling will be used in TF.
  [0] ASTC_MULTICYCLE_TF_FORCE_F16 rw — When set, ASTC encoded texels that are filtered over multiple cycles by the TF will be output from the MADD as F16.
0x17C8 CORE_MMRS_RGX_CR_TPU_MADD_VDM_CTRL reset 0x2 — Global control to MADD for vertex data master
  [2] MADD_CONFIG_DXT35_TRANSOVR rw — When set this disables alternative mode implied by colour0 > colour1 for DXT3 to DXT5
  [1] ASTC_ODD_SCALING_ENABLE rw — When set, ASTC encoded texels use the odd U16->F16 scaling in the TF. When zero, the usual scaling will be used in TF.
  [0] ASTC_MULTICYCLE_TF_FORCE_F16 rw — When set, ASTC encoded texels that are filtered over multiple cycles by the TF will be output from the MADD as F16.
0x17D0 CORE_MMRS_RGX_CR_TPU_MADD_CDM_CTRL reset 0x2 — Global control to MADD for compute data master
  fields as CORE_MMRS_RGX_CR_TPU_MADD_VDM_CTRL
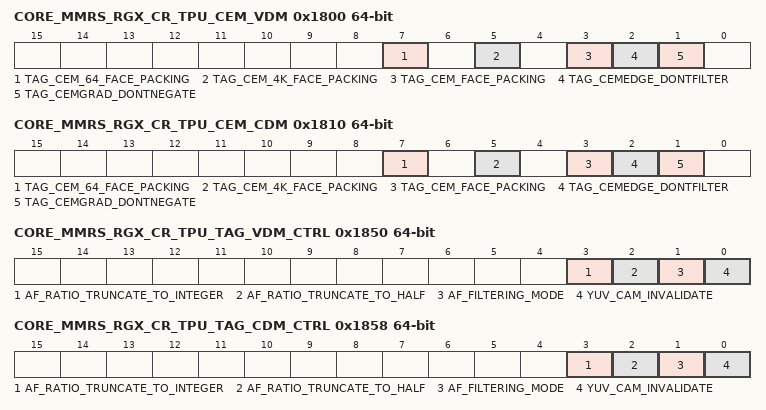
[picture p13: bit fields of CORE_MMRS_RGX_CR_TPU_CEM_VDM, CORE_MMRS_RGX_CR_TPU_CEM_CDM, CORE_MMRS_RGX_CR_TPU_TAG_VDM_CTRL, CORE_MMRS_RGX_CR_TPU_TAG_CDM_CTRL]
0x1800 CORE_MMRS_RGX_CR_TPU_CEM_VDM — Global control to CEM textures for vertex data master
  [7] TAG_CEM_64_FACE_PACKING rw — Vertex data master. Enable 64-byte alignment between CEM faces when set to 1. It applies for both when mipmap is enabled or disabled
  [5] TAG_CEM_4K_FACE_PACKING rw — Vertex data master. Enable 4K-byte alignment between CEM faces when set to 1. It applies for both when mipmap is enabled or disabled
  [3] TAG_CEM_FACE_PACKING rw — Vertex data master. Enable dword alignment between CEM faces when set to 1
  [2] TAG_CEMEDGE_DONTFILTER rw — Vertex data master. Disable filtering over edges/corners for CEM. When set to 1, HW will be seemfull, ie, always stay in the current map, always honour the addressmode. When set to 0, HW will be seemless, ie, ignore addressmode, filter between faces at the edges/corners
  [1] TAG_CEMGRAD_DONTNEGATE rw — Vertex data master. Disable negation for user supplied gradients for cem swap i. e. will only swap dudx etc not negate
0x1810 CORE_MMRS_RGX_CR_TPU_CEM_CDM — Global control to CEM textures for compute data master
  [7] TAG_CEM_64_FACE_PACKING rw — Compute data master. Enable 64-byte alignment between CEM faces when set to 1. It applies for both when mipmap is enabled or disabled
  [5] TAG_CEM_4K_FACE_PACKING rw — Compute data master. Enable 4K-byte alignment between CEM faces when set to 1. It applies for both when mipmap is enabled or disabled
  [3] TAG_CEM_FACE_PACKING rw — Compute data master. Enable dword alignment between CEM faces when set to 1
  [2] TAG_CEMEDGE_DONTFILTER rw — Compute data master. Disable filtering over edges/corners for CEM. When set to 1, HW will be seemfull, ie, always stay in the current map, always honour the addressmode. When set to 0, HW will be seemless, ie, ignore addressmode, filter between faces at the edges/corners
  [1] TAG_CEMGRAD_DONTNEGATE rw — Compute data master. Disable negation for user supplied gradients for cem swap i. e. will only swap dudx etc not negate
0x1850 CORE_MMRS_RGX_CR_TPU_TAG_VDM_CTRL — Global control to TAG for the vertex data master
  fields as CORE_MMRS_RGX_CR_TPU_TAG_CTRL
0x1858 CORE_MMRS_RGX_CR_TPU_TAG_CDM_CTRL — Global control to TAG for the compute data master
  fields as CORE_MMRS_RGX_CR_TPU_TAG_CTRL
0x1870 CORE_MMRS_RGX_CR_TPU_VDM_YUV_CSC_COEFFICIENTS — Base address for the YUV CSC set of coefficients stored in memory for the compute data master
  fields as CORE_MMRS_RGX_CR_TPU_YUV_CSC_COEFFICIENTS
0x1878 CORE_MMRS_RGX_CR_TPU_CDM_YUV_CSC_COEFFICIENTS — Base address for the YUV CSC set of coefficients stored in memory for the compute data master
  fields as CORE_MMRS_RGX_CR_TPU_YUV_CSC_COEFFICIENTS
0x18C0 CORE_MMRS_RGX_CR_TPU_LODBIASREP_CMP_MANTISSA_MASK_PDM reset 0x7FFFFF — Mask for comparing mantissa of f32 LOD Bias/Replace value for PPLOD speedup for the pixel data master
  [22:0] LODBIASREP_CMP_MANTISSA_MASK rw — Mask for comparing mantissa of f32 LOD Bias/Replace value for PPLOD speedup
0x18C8 CORE_MMRS_RGX_CR_TPU_LODBIASREP_CMP_MANTISSA_MASK_VDM reset 0x7FFFFF — Mask for comparing mantissa of f32 LOD Bias/Replace value for PPLOD speedup for the vertex data master
  fields as CORE_MMRS_RGX_CR_TPU_LODBIASREP_CMP_MANTISSA_MASK_PDM
0x18D0 CORE_MMRS_RGX_CR_TPU_LODBIASREP_CMP_MANTISSA_MASK_CDM reset 0x7FFFFF — Mask for comparing mantissa of f32 LOD Bias/Replace value for PPLOD speedup for the compute data master
  fields as CORE_MMRS_RGX_CR_TPU_LODBIASREP_CMP_MANTISSA_MASK_PDM
0x18E8 CORE_MMRS_RGX_CR_TPU_TAG_LOD_TRI_FRAC_MASK — Mask to enable/disable and set accuracy of Trilinear performance optimisation. Brilinear snapping.
  [3:0] TAG_LOD_TRI_FRAC_MASK rw — Mask to enable/disable and set accuracy of Trilinear performance optimisation. Mask bit 1 => corresponding trilinear fraction LSB rounding enabled, 0 => disabled. Only 4 LSBs of 4.8 LOD fixed point value can be rounded up/down to 0
0x18F0 CORE_MMRS_RGX_CR_TPU_TAG_LOD_TRI_FRAC_MASK_VDM — Mask to enable/disable and set accuracy of Trilinear performance optimisation. Brilinear snapping. Vertex data master.
  fields as CORE_MMRS_RGX_CR_TPU_TAG_LOD_TRI_FRAC_MASK
0x18F8 CORE_MMRS_RGX_CR_TPU_TAG_LOD_TRI_FRAC_MASK_CDM — Mask to enable/disable and set accuracy of Trilinear performance optimisation. Brilinear snapping. Compute data master.
  fields as CORE_MMRS_RGX_CR_TPU_TAG_LOD_TRI_FRAC_MASK
{0x1A00+8i} CORE_MMRS_RGX_CR_SCRATCH{i} (i=0..15) — Internal 'scratch' register for debug use by the firmware.
  [31:0] DATA rw
{0x1A80+0x10000*i} CORE_MMRS_RGX_CR_OS{i}_SCRATCH0 (i=0..7)
  [31:0] DATA rw
{0x1A88+0x10000*i} CORE_MMRS_RGX_CR_OS{i}_SCRATCH1 (i=0..7)
  [31:0] DATA rw
{0x1A90+0x10000*i} CORE_MMRS_RGX_CR_OS{i}_SCRATCH2 (i=0..7)
  [7:0] DATA rw
{0x1A98+0x10000*i} CORE_MMRS_RGX_CR_OS{i}_SCRATCH3 (i=0..7)
  [7:0] DATA rw
0x2000 CORE_MMRS_RGX_CR_PM_TA_MMUPAGE_STATUS ro
  [21:0] OP — MMU pages[4KB] counter @ the TA context
0x2008 CORE_MMRS_RGX_CR_PM_3D_MMUPAGE_STATUS ro
  [21:0] OP — MMU pages[4KB] counter @ the 3D context
